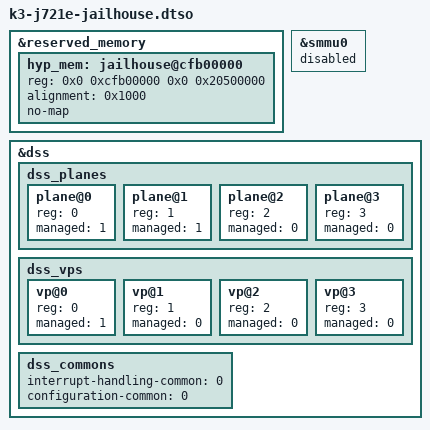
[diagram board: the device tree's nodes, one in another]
// SPDX-License-Identifier: GPL-2.0
/*
 * Copyright (C) 2019 Texas Instruments Incorporated - http://www.ti.com/
 */

/dts-v1/;
/plugin/;

&reserved_memory {
	#address-cells = <2>;
	#size-cells = <2>;

	/*
	 * Reserve for Jailhouse hypervisor firmware and inmates.
	 * Must be in sync with jailhouse cell configurations.
	 */
	hyp_mem: jailhouse@cfb00000 {
		reg = <0x0 0xcfb00000 0x0 0x20500000>;
		alignment = <0x1000>;
		no-map;
	};
};

&smmu0 {
	status = "disabled";
};

&dss {

	dss_planes: dss_planes {
		#address-cells = <1>;
		#size-cells = <0>;

		/*vid1*/
		plane@0 {
			reg = <0>;
			managed = <1>;
		};

		/*vidl1*/
		plane@1 {
			reg = <1>;
			managed = <1>;
		};

		/*vid2*/
		plane@2 {
			reg = <2>;
			managed = <0>;
		};

		/*vidl2*/
		plane@3 {
			reg = <3>;
			managed = <0>;
		};
	};

	dss_vps: dss_vps {
		#address-cells = <1>;
		#size-cells = <0>;

		vp@0 {
			reg = <0>;
			managed = <1>;
		};

		vp@1 {
			reg = <1>;
			managed = <0>;
		};

		vp@2 {
			reg = <2>;
			managed = <0>;
		};

		vp@3 {
			reg = <3>;
			managed = <0>;
		};
	};

	dss_commons: dss_commons {
		#address-cells = <0>;
		#size-cells = <0>;
		interrupt-handling-common = <0>;
		configuration-common = <0>;
	};
};
